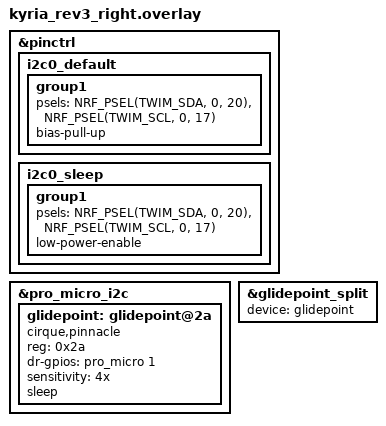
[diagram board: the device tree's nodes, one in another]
// Pull in the shared configuration
#include "shared.dtsi"

&pinctrl {
    i2c0_default {
        group1 {
            psels = <NRF_PSEL(TWIM_SDA, 0, 20)>,
                <NRF_PSEL(TWIM_SCL, 0, 17)>;
            bias-pull-up;
        };
    };
    i2c0_sleep: i2c0_sleep {
        group1 {
            psels = <NRF_PSEL(TWIM_SDA, 0, 20)>,
                <NRF_PSEL(TWIM_SCL, 0, 17)>;
            low-power-enable;
        };
    };
};

&pro_micro_i2c {
    status = "okay";
    glidepoint: glidepoint@2a {
        compatible = "cirque,pinnacle";
        reg = <0x2a>;
        status = "okay";
        dr-gpios = <&pro_micro 1 (GPIO_ACTIVE_HIGH)>;

        sensitivity = "4x";
        sleep;
    };
};

// Overrides for the input-split child node
&glidepoint_split {
    device = <&glidepoint>;
};
